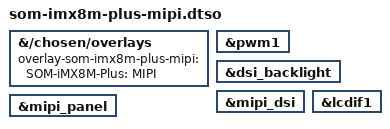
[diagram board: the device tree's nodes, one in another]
#include "overlay.h"

&{/chosen/overlays} {
	overlay-som-imx8m-plus-mipi = "SOM-iMX8M-Plus: MIPI";
};

&pwm1 {
	status = "okay";
};

&dsi_backlight {
	status = "okay";
};

&mipi_dsi {
	status = "okay";
};

&mipi_panel {
		status = "okay";
};

&lcdif1 {
	status = "okay";
};
